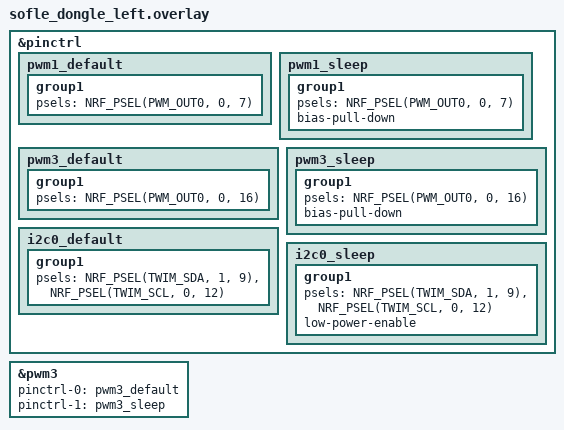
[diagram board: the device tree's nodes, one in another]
/*
 * 左半「模块插座」的引脚定义（设备树那一半）。
 *
 * 这里写的是「插座上的哪根线接到 MCU 的哪只脚」，与插的是轨迹球还是触摸板
 * 无关——左座两个模块复用同一批导线（见 MODULAR_POINTER_ANALYSIS.md §4.1）：
 *
 *   轨迹球 UP   P0.05  =  触摸板 MOTION
 *   轨迹球 LEFT P0.12  =  触摸板 I2C SCL
 *   轨迹球 DOWN P1.09  =  触摸板 I2C SDA
 *   轨迹球 RIGHT P0.27 =  （触摸板不用）
 *
 * 放在板级 overlay 而不是 shield 里，是因为它属于「板子」而不是「模块」：
 * shield 那边只负责把外设 enable 起来（&pwm1 / &pwm3 / &i2c0），
 * 引脚本身在 config/<board>.overlay 里单点定义，换模块不用动。
 *
 * 驱动里那几根 GPIO 方向线/MOTION 线的引脚号在 .conf 里（Kconfig），
 * 见 config/sofle_dongle_left.conf。
 */

&pinctrl {
    /* 模块主 LED：轨迹球和触摸板共用同一颗 */
    pwm1_default: pwm1_default {
        group1 {
            psels = <NRF_PSEL(PWM_OUT0, 0, 7)>;
        };
    };

    pwm1_sleep: pwm1_sleep {
        group1 {
            psels = <NRF_PSEL(PWM_OUT0, 0, 7)>;
            bias-pull-down;
        };
    };

    /* 触摸板自己加的那颗 LED —— 只有左板引出来了，enable 也一并留在这
     * 里而不是 shield 里（bbtrackpad.overlay 引用了 pwm3_default，
     * 放 shield 会让右板在设备树阶段就炸，见那边的注释） */
    pwm3_default: pwm3_default {
        group1 {
            psels = <NRF_PSEL(PWM_OUT0, 0, 16)>;
        };
    };

    pwm3_sleep: pwm3_sleep {
        group1 {
            psels = <NRF_PSEL(PWM_OUT0, 0, 16)>;
            bias-pull-down;
        };
    };

    /* 模块插座上的 I2C，只有触摸板会用（轨迹球拿这两根当方向线） */
    i2c0_default: i2c0_default {
        group1 {
            psels = <NRF_PSEL(TWIM_SDA, 1, 9)>,
                    <NRF_PSEL(TWIM_SCL, 0, 12)>;
        };
    };

    i2c0_sleep: i2c0_sleep {
        group1 {
            psels = <NRF_PSEL(TWIM_SDA, 1, 9)>,
                    <NRF_PSEL(TWIM_SCL, 0, 12)>;
            low-power-enable;
        };
    };
};

/*
 * 触摸板副 LED 的 enable。本来在 bbtrackpad.overlay 里，但那条 enable 引用
 * pwm3_default —— 引脚是板级的，插触摸板才有消费者，插轨迹球时这里只是
 * 留一个没人用的 PWM 设备（开销可忽略）。
 */
&pwm3 {
    status = "okay";
    pinctrl-0 = <&pwm3_default>;
    pinctrl-1 = <&pwm3_sleep>;
    pinctrl-names = "default", "sleep";
};
